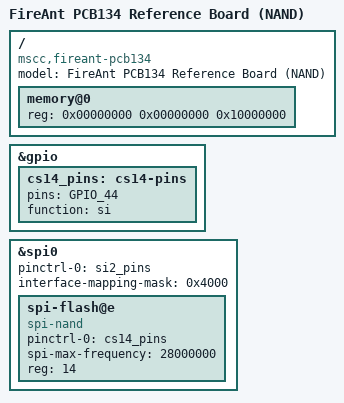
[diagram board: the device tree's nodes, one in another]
// SPDX-License-Identifier: (GPL-2.0+ OR MIT)
/*
 * Copyright (c) 2018 Microsemi Corporation
 */

/dts-v1/;
#include "fireant_pcb134_board.dtsi"

/ {
	model = "FireAnt PCB134 Reference Board (NAND)";
	compatible = "mscc,fireant-pcb134", "mscc,fireant";

	memory@0 {
		device_type = "memory";
		reg = <0x00000000 0x00000000 0x10000000>;
	};
};

&gpio {
	cs14_pins: cs14-pins {
		pins = "GPIO_44";
		function = "si";
	};
};

&spi0 {
	pinctrl-0 = <&si2_pins>;
	pinctrl-names = "default";
	interface-mapping-mask = <0x4000>;	// NAND CS14 = SPI2
	// Dedicated SPI2 interface
	spi-flash@e {
		compatible = "spi-nand";
		pinctrl-0 = <&cs14_pins>;
		pinctrl-names = "default";
		spi-max-frequency = <28000000>;
		reg = <14>;
	};
};
